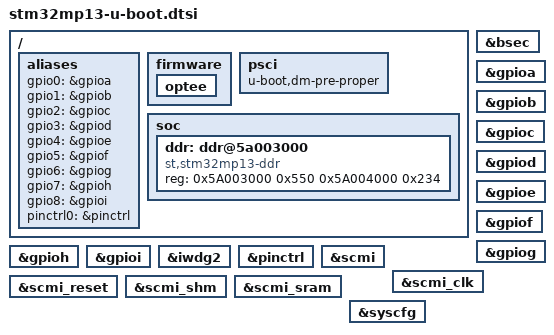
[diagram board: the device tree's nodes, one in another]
// SPDX-License-Identifier: GPL-2.0-or-later OR BSD-3-Clause
/*
 * Copyright (C) 2022, STMicroelectronics - All Rights Reserved
 */

/ {
	aliases {
		gpio0 = &gpioa;
		gpio1 = &gpiob;
		gpio2 = &gpioc;
		gpio3 = &gpiod;
		gpio4 = &gpioe;
		gpio5 = &gpiof;
		gpio6 = &gpiog;
		gpio7 = &gpioh;
		gpio8 = &gpioi;
		pinctrl0 = &pinctrl;
	};

	firmware {
		optee {
			u-boot,dm-all;
		};
	};

	/* need PSCI for sysreset during board_f */
	psci {
		u-boot,dm-pre-proper;
	};

	soc {
		u-boot,dm-all;

		ddr: ddr@5a003000 {
			u-boot,dm-all;

			compatible = "st,stm32mp13-ddr";

			reg = <0x5A003000 0x550
			       0x5A004000 0x234>;

			status = "okay";
		};
	};
};

&bsec {
	u-boot,dm-all;
};

&gpioa {
	u-boot,dm-all;
};

&gpiob {
	u-boot,dm-all;
};

&gpioc {
	u-boot,dm-all;
};

&gpiod {
	u-boot,dm-all;
};

&gpioe {
	u-boot,dm-all;
};

&gpiof {
	u-boot,dm-all;
};

&gpiog {
	u-boot,dm-all;
};

&gpioh {
	u-boot,dm-all;
};

&gpioi {
	u-boot,dm-all;
};

&iwdg2 {
	u-boot,dm-all;
};

&pinctrl {
	u-boot,dm-all;
};

&scmi {
	u-boot,dm-all;
};

&scmi_clk {
	u-boot,dm-all;
};

&scmi_reset {
	u-boot,dm-all;
};

&scmi_shm {
	u-boot,dm-all;
};

&scmi_sram {
	u-boot,dm-all;
};

&syscfg {
	u-boot,dm-all;
};
